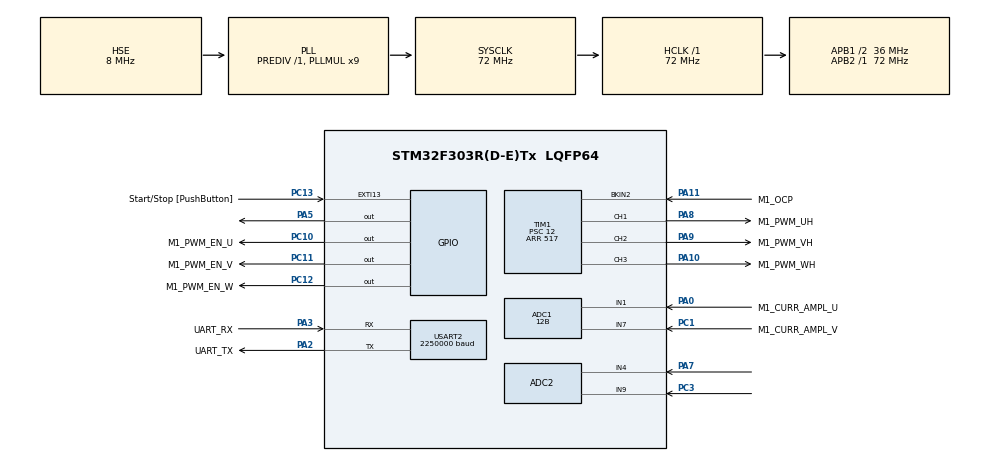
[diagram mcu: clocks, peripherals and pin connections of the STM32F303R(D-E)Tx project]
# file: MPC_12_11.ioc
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ADC1.Channel-1\#ChannelRegularConversion=ADC_CHANNEL_1
ADC1.Channel-2\#ChannelRegularConversion=ADC_CHANNEL_7
ADC1.ContinuousConvMode=ENABLE
ADC1.DMAContinuousRequests=DISABLE
ADC1.DataAlign=ADC_DATAALIGN_RIGHT
ADC1.DiscontinuousConvMode=DISABLE
ADC1.EOCSelection=ADC_EOC_SINGLE_CONV
ADC1.EnableAnalogWatchDog1=false
ADC1.EnableAnalogWatchDog2=false
ADC1.EnableAnalogWatchDog3=false
ADC1.EnableInjectedConversion=DISABLE
ADC1.EnableRegularConversion=ENABLE
ADC1.ExternalTrigConv=ADC_SOFTWARE_START
ADC1.ExternalTrigConvEdge=ADC_EXTERNALTRIGCONVEDGE_NONE
ADC1.LowPowerAutoWait=DISABLE
ADC1.NbrOfConversion=2
ADC1.NbrOfConversionFlag=1
ADC1.Offset-1\#ChannelRegularConversion=0
ADC1.Offset-2\#ChannelRegularConversion=0
ADC1.OffsetNumber-1\#ChannelRegularConversion=ADC_OFFSET_NONE
ADC1.OffsetNumber-2\#ChannelRegularConversion=ADC_OFFSET_NONE
ADC1.Overrun=ADC_OVR_DATA_OVERWRITTEN
ADC1.Rank-1\#ChannelRegularConversion=1
ADC1.Rank-2\#ChannelRegularConversion=2
ADC1.Resolution=ADC_RESOLUTION_12B
ADC1.SamplingTime-1\#ChannelRegularConversion=ADC_SAMPLETIME_1CYCLE_5
ADC1.SamplingTime-2\#ChannelRegularConversion=ADC_SAMPLETIME_1CYCLE_5
ADC1.ScanConvMode=ADC_SCAN_ENABLE
ADC1.master=1
ADC2.Channel-19\#ChannelRegularConversion=ADC_CHANNEL_4
ADC2.Channel-20\#ChannelRegularConversion=ADC_CHANNEL_9
ADC2.ContinuousConvMode=ENABLE
ADC2.NbrOfConversion=2
ADC2.NbrOfConversionFlag=1
ADC2.Offset-19\#ChannelRegularConversion=0
ADC2.Offset-20\#ChannelRegularConversion=0
ADC2.OffsetNumber-19\#ChannelRegularConversion=ADC_OFFSET_NONE
ADC2.OffsetNumber-20\#ChannelRegularConversion=ADC_OFFSET_NONE
ADC2.Rank-19\#ChannelRegularConversion=1
ADC2.Rank-20\#ChannelRegularConversion=2
ADC2.SamplingTime-19\#ChannelRegularConversion=ADC_SAMPLETIME_1CYCLE_5
ADC2.SamplingTime-20\#ChannelRegularConversion=ADC_SAMPLETIME_1CYCLE_5
Dma.ADC1.2.Direction=DMA_PERIPH_TO_MEMORY
Dma.ADC1.2.Instance=DMA1_Channel1
Dma.ADC1.2.MemDataAlignment=DMA_MDATAALIGN_WORD
Dma.ADC1.2.MemInc=DMA_MINC_ENABLE
Dma.ADC1.2.Mode=DMA_CIRCULAR
Dma.ADC1.2.PeriphDataAlignment=DMA_PDATAALIGN_WORD
Dma.ADC1.2.PeriphInc=DMA_PINC_DISABLE
Dma.ADC1.2.Priority=DMA_PRIORITY_LOW
Dma.ADC2.3.Direction=DMA_PERIPH_TO_MEMORY
Dma.ADC2.3.Instance=DMA2_Channel1
Dma.ADC2.3.MemDataAlignment=DMA_MDATAALIGN_WORD
Dma.ADC2.3.MemInc=DMA_MINC_ENABLE
Dma.ADC2.3.Mode=DMA_CIRCULAR
Dma.ADC2.3.PeriphDataAlignment=DMA_PDATAALIGN_WORD
Dma.ADC2.3.PeriphInc=DMA_PINC_DISABLE
Dma.ADC2.3.Priority=DMA_PRIORITY_LOW
Dma.Request0=USART2_RX
Dma.Request1=USART2_TX
Dma.Request2=ADC1
Dma.Request3=ADC2
Dma.USART2_RX.0.Direction=DMA_PERIPH_TO_MEMORY
Dma.USART2_RX.0.Instance=DMA1_Channel6
Dma.USART2_RX.0.MemDataAlignment=DMA_MDATAALIGN_BYTE
Dma.USART2_RX.0.MemInc=DMA_MINC_ENABLE
Dma.USART2_RX.0.Mode=DMA_CIRCULAR
Dma.USART2_RX.0.PeriphDataAlignment=DMA_PDATAALIGN_BYTE
Dma.USART2_RX.0.PeriphInc=DMA_PINC_DISABLE
Dma.USART2_RX.0.Priority=DMA_PRIORITY_LOW
Dma.USART2_TX.1.Direction=DMA_MEMORY_TO_PERIPH
Dma.USART2_TX.1.Instance=DMA1_Channel7
Dma.USART2_TX.1.MemDataAlignment=DMA_MDATAALIGN_BYTE
Dma.USART2_TX.1.MemInc=DMA_MINC_ENABLE
Dma.USART2_TX.1.Mode=DMA_NORMAL
Dma.USART2_TX.1.PeriphDataAlignment=DMA_PDATAALIGN_BYTE
Dma.USART2_TX.1.PeriphInc=DMA_PINC_DISABLE
Dma.USART2_TX.1.Priority=DMA_PRIORITY_LOW
Mcu.Family=STM32F3
Mcu.Name=STM32F303R(D-E)Tx
Mcu.Package=LQFP64
NVIC.EXTI15_10_IRQn=true\:3\:0\:false\:false\:true\:true\:true
NVIC.PriorityGroup=NVIC_PRIORITYGROUP_3
NVIC.TIM1_CC_IRQn=true\:0\:0\:false\:true\:true\:1\:true\:true
PA0.GPIO_Label=M1_CURR_AMPL_U
PA0.Mode=IN1-Single-Ended
PA0.Signal=ADC1_IN1
PA10.GPIO_Label=M1_PWM_WH
PA10.GPIO_PuPd=GPIO_PULLDOWN
PA10.GPIO_Speed=GPIO_SPEED_FREQ_HIGH
PA10.Signal=S_TIM1_CH3
PA11.GPIO_Label=M1_OCP
PA11.GPIO_PuPd=GPIO_PULLUP
PA11.Mode=Activate-Break-Input-2
PA11.Signal=TIM1_BKIN2
PA13.GPIO_Label=TMS
PA13.Mode=Serial_Wire
PA13.Signal=SYS_JTMS-SWDIO
PA14.GPIO_Label=TCK
PA14.Mode=Serial_Wire
PA14.Signal=SYS_JTCK-SWCLK
PA2.GPIO_Label=UART_TX
PA2.GPIO_Mode=GPIO_MODE_AF_PP
PA2.GPIO_PuPd=GPIO_NOPULL
PA2.GPIO_Speed=GPIO_SPEED_FREQ_LOW
PA2.Mode=Asynchronous
PA2.Signal=USART2_TX
PA3.GPIO_Label=UART_RX
PA3.GPIO_Mode=GPIO_MODE_AF_PP
PA3.GPIO_PuPd=GPIO_NOPULL
PA3.GPIO_Speed=GPIO_SPEED_FREQ_LOW
PA3.Mode=Asynchronous
PA3.Signal=USART2_RX
PA5.Signal=GPIO_Output
PA7.Mode=IN4-Single-Ended
PA7.Signal=ADC2_IN4
PA8.GPIO_Label=M1_PWM_UH
PA8.GPIO_PuPd=GPIO_PULLDOWN
PA8.GPIO_Speed=GPIO_SPEED_FREQ_HIGH
PA8.Signal=S_TIM1_CH1
PA9.GPIO_Label=M1_PWM_VH
PA9.GPIO_PuPd=GPIO_PULLDOWN
PA9.GPIO_Speed=GPIO_SPEED_FREQ_HIGH
PA9.Signal=S_TIM1_CH2
PC1.GPIO_Label=M1_CURR_AMPL_V
PC1.Signal=ADCx_IN7
PC10.GPIO_Label=M1_PWM_EN_U
PC10.GPIO_PuPd=GPIO_PULLDOWN
PC10.GPIO_Speed=GPIO_SPEED_FREQ_HIGH
PC10.Signal=GPIO_Output
PC11.GPIO_Label=M1_PWM_EN_V
PC11.GPIO_PuPd=GPIO_PULLDOWN
PC11.GPIO_Speed=GPIO_SPEED_FREQ_HIGH
PC11.Signal=GPIO_Output
PC12.GPIO_Label=M1_PWM_EN_W
PC12.GPIO_PuPd=GPIO_PULLDOWN
PC12.GPIO_Speed=GPIO_SPEED_FREQ_HIGH
PC12.Signal=GPIO_Output
PC13.GPIO_Label=Start/Stop [PushButton]
PC13.GPIO_ModeDefaultEXTI=GPIO_MODE_IT_FALLING
PC13.GPIO_PuPd=GPIO_NOPULL
PC13.Signal=GPXTI13
PC3.Signal=ADCx_IN9
PF0-OSC_IN.Mode=HSE-External-Oscillator
PF0-OSC_IN.Signal=RCC_OSC_IN
PF1-OSC_OUT.Mode=HSE-External-Oscillator
PF1-OSC_OUT.Signal=RCC_OSC_OUT
ProjectManager.HeapSize=0x200
ProjectManager.StackSize=0x400
ProjectManager.TargetToolchain=STM32CubeIDE
RCC.AHBFreq_Value=72000000
RCC.APB1CLKDivider=RCC_HCLK_DIV2
RCC.APB1Freq_Value=36000000
RCC.APB1TimFreq_Value=72000000
RCC.APB2Freq_Value=72000000
RCC.APB2TimFreq_Value=72000000
RCC.CortexFreq_Value=72000000
RCC.HCLKFreq_Value=72000000
RCC.HSE_VALUE=8000000
RCC.HSI_VALUE=8000000
RCC.LSE_VALUE=32768
RCC.PLLMUL=RCC_PLL_MUL9
RCC.PLLSourceVirtual=RCC_PLLSOURCE_HSE
RCC.SYSCLKFreq_VALUE=72000000
RCC.SYSCLKSourceVirtual=RCC_SYSCLKSOURCE_PLLCLK
RCC.TIM1Selection=RCC_TIM1CLK_PLLCLK
RCC.TIM34Selection=RCC_TIM34CLK_PLLCLK
RCC.TIM8Selection=RCC_TIM8CLK_PLLCLK
RCC.USBFreq_Value=72000000
RCC.Usart2ClockSelection=RCC_USART2CLKSOURCE_SYSCLK
SH.ADCx_IN7.0=ADC1_IN7,IN7-Single-Ended
SH.ADCx_IN9.0=ADC2_IN9,IN9-Single-Ended
SH.S_TIM1_CH1.0=TIM1_CH1,PWM Generation1 CH1
SH.S_TIM1_CH2.0=TIM1_CH2,PWM Generation2 CH2
SH.S_TIM1_CH3.0=TIM1_CH3,PWM Generation3 CH3
TIM1.AutoReloadPreload=TIM_AUTORELOAD_PRELOAD_ENABLE
TIM1.AutomaticOutput=TIM_AUTOMATICOUTPUT_DISABLE
TIM1.Break2Filter=3
TIM1.Break2Polarity=TIM_BREAK2POLARITY_LOW
TIM1.Break2State=TIM_BREAK2_ENABLE
TIM1.BreakFilter=0
TIM1.BreakPolarity=TIM_BREAKPOLARITY_HIGH
TIM1.BreakState=TIM_BREAK_DISABLE
TIM1.Channel-PWM\ Generation1\ CH1=TIM_CHANNEL_1
TIM1.Channel-PWM\ Generation2\ CH2=TIM_CHANNEL_2
TIM1.Channel-PWM\ Generation3\ CH3=TIM_CHANNEL_3
TIM1.Channel-PWM\ Generation4\ No\ Output=TIM_CHANNEL_4
TIM1.ClearInputSource=TIM_CLEARINPUTSOURCE_NONE
TIM1.ClockDivision=TIM_CLOCKDIVISION_DIV1
TIM1.CounterMode=TIM_COUNTERMODE_CENTERALIGNED1
TIM1.LockLevel=TIM_LOCKLEVEL_1
TIM1.OCIdleState_1=TIM_OCIDLESTATE_RESET
TIM1.OCIdleState_2=TIM_OCIDLESTATE_RESET
TIM1.OCIdleState_3=TIM_OCIDLESTATE_RESET
TIM1.OCIdleState_4=TIM_OCIDLESTATE_RESET
TIM1.OCMode_PWM-PWM\ Generation1\ CH1=TIM_OCMODE_PWM1
TIM1.OCMode_PWM-PWM\ Generation2\ CH2=TIM_OCMODE_PWM1
TIM1.OCMode_PWM-PWM\ Generation3\ CH3=TIM_OCMODE_PWM1
TIM1.OCMode_PWM-PWM\ Generation4\ No\ Output=TIM_OCMODE_PWM2
TIM1.OCPolarity_1=TIM_OCPOLARITY_HIGH
TIM1.OCPolarity_2=TIM_OCPOLARITY_HIGH
TIM1.OCPolarity_3=TIM_OCPOLARITY_HIGH
TIM1.OCPolarity_4=TIM_OCPOLARITY_HIGH
TIM1.OffStateIDLEMode=TIM_OSSI_ENABLE
TIM1.OffStateRunMode=TIM_OSSR_ENABLE
TIM1.Period=517
TIM1.Prescaler=12
TIM1.Pulse-PWM\ Generation1\ CH1=0
TIM1.Pulse-PWM\ Generation2\ CH2=0
TIM1.Pulse-PWM\ Generation3\ CH3=0
TIM1.Pulse-PWM\ Generation4\ No\ Output=512
TIM1.RepetitionCounter=0
TIM1.TIM_MasterOutputTrigger=TIM_TRGO_OC4REF
TIM1.TIM_MasterOutputTrigger2=TIM_TRGO2_UPDATE
TIM1.TIM_MasterSlaveMode=TIM_MASTERSLAVEMODE_DISABLE
USART2.BaudRate=2250000
USART2.DMADisableonRxErrorParam=ADVFEATURE_DMA_DISABLEONRXERROR
USART2.OneBitSampling=UART_ONE_BIT_SAMPLE_ENABLE
USART2.OverSampling=UART_OVERSAMPLING_8
USART2.VirtualMode-Asynchronous=VM_ASYNC
USART2.WordLength=WORDLENGTH_8B
VP_TIM1_VS_ClockSourceINT.Mode=Internal
VP_TIM1_VS_no_output4.Mode=PWM Generation4 No Output
board=custom

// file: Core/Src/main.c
/* USER CODE BEGIN Header */
/**
  ******************************************************************************
  * @file           : main.c
  * @brief          : Main program body
  ******************************************************************************
  * @attention
  *
  * <h2><center>&copy; Copyright (c) 2021 STMicroelectronics.
  * All rights reserved.</center></h2>
  *
  * This software component is licensed by ST under Ultimate Liberty license
  * SLA0044, the "License"; You may not use this file except in compliance with
  * the License. You may obtain a copy of the License at:
  *                             www.st.com/SLA0044
  *
  ******************************************************************************
  */
/* USER CODE END Header */
#include "main.h"

/* USER CODE BEGIN Includes */
//
//#include <string.h>
//#include <stdio.h>
/* USER CODE END Includes */

ADC_HandleTypeDef hadc1;
ADC_HandleTypeDef hadc2;
DMA_HandleTypeDef hdma_adc1;
DMA_HandleTypeDef hdma_adc2;

TIM_HandleTypeDef htim1;

UART_HandleTypeDef huart2;
DMA_HandleTypeDef hdma_usart2_rx;
DMA_HandleTypeDef hdma_usart2_tx;

void SystemClock_Config(void);
static void MX_GPIO_Init(void);
static void MX_DMA_Init(void);
static void MX_ADC1_Init(void);
static void MX_TIM1_Init(void);
static void MX_USART2_UART_Init(void);
static void MX_ADC2_Init(void);
static void MX_NVIC_Init(void);

int main(void)
{

  /* MCU Configuration--------------------------------------------------------*/

  /* Reset of all peripherals, Initializes the Flash interface and the Systick. */
  HAL_Init();

  /* Configure the system clock */
  SystemClock_Config();

  /* Initialize all configured peripherals */
  MX_GPIO_Init();
  MX_DMA_Init();
  MX_ADC1_Init();
  MX_TIM1_Init();
  MX_USART2_UART_Init();
  MX_ADC2_Init();

  /* Initialize interrupts */
  MX_NVIC_Init();
  /* USER CODE BEGIN 2 */

  	// Calibrate ADCs
	HAL_ADCEx_Calibration_Start(&hadc1, ADC_SINGLE_ENDED);
	HAL_ADCEx_Calibration_Start(&hadc2, ADC_SINGLE_ENDED);

	// Enable MOSFET drivers
	HAL_GPIO_WritePin(GPIOC, GPIO_PIN_10, 1);
	HAL_GPIO_WritePin(GPIOC, GPIO_PIN_11, 1);
	HAL_GPIO_WritePin(GPIOC, GPIO_PIN_12, 1);

	// Start timers
	HAL_TIM_PWM_Start_IT(&htim1, TIM_CHANNEL_4);
	HAL_TIM_PWM_Start(&htim1, TIM_CHANNEL_1);
	HAL_TIM_PWM_Start(&htim1, TIM_CHANNEL_2);
	HAL_TIM_PWM_Start(&htim1, TIM_CHANNEL_3);

  /* USER CODE END 2 */

  /* Infinite loop */
  while (1)
  {

  }
}

void SystemClock_Config(void)
{
  RCC_OscInitTypeDef RCC_OscInitStruct = {0};
  RCC_ClkInitTypeDef RCC_ClkInitStruct = {0};
  RCC_PeriphCLKInitTypeDef PeriphClkInit = {0};

  /** Initializes the RCC Oscillators according to the specified parameters
  * in the RCC_OscInitTypeDef structure.
  */
  RCC_OscInitStruct.OscillatorType = RCC_OSCILLATORTYPE_HSE;
  RCC_OscInitStruct.HSEState = RCC_HSE_ON;
  RCC_OscInitStruct.HSIState = RCC_HSI_ON;
  RCC_OscInitStruct.PLL.PLLState = RCC_PLL_ON;
  RCC_OscInitStruct.PLL.PLLSource = RCC_PLLSOURCE_HSE;
  RCC_OscInitStruct.PLL.PLLMUL = RCC_PLL_MUL9;
  RCC_OscInitStruct.PLL.PREDIV = RCC_PREDIV_DIV1;
  if (HAL_RCC_OscConfig(&RCC_OscInitStruct) != HAL_OK)
  {
    Error_Handler();
  }
  /** Initializes the CPU, AHB and APB buses clocks
  */
  RCC_ClkInitStruct.ClockType = RCC_CLOCKTYPE_HCLK|RCC_CLOCKTYPE_SYSCLK
                              |RCC_CLOCKTYPE_PCLK1|RCC_CLOCKTYPE_PCLK2;
  RCC_ClkInitStruct.SYSCLKSource = RCC_SYSCLKSOURCE_PLLCLK;
  RCC_ClkInitStruct.AHBCLKDivider = RCC_SYSCLK_DIV1;
  RCC_ClkInitStruct.APB1CLKDivider = RCC_HCLK_DIV2;
  RCC_ClkInitStruct.APB2CLKDivider = RCC_HCLK_DIV1;

  if (HAL_RCC_ClockConfig(&RCC_ClkInitStruct, FLASH_LATENCY_2) != HAL_OK)
  {
    Error_Handler();
  }
  PeriphClkInit.PeriphClockSelection = RCC_PERIPHCLK_USART2|RCC_PERIPHCLK_TIM1
                              |RCC_PERIPHCLK_ADC12;
  PeriphClkInit.Usart2ClockSelection = RCC_USART2CLKSOURCE_SYSCLK;
  PeriphClkInit.Adc12ClockSelection = RCC_ADC12PLLCLK_DIV1;
  PeriphClkInit.Tim1ClockSelection = RCC_TIM1CLK_PLLCLK;
  if (HAL_RCCEx_PeriphCLKConfig(&PeriphClkInit) != HAL_OK)
  {
    Error_Handler();
  }
}

/**
  * @brief NVIC Configuration.
  * @retval None
  */
static void MX_NVIC_Init(void)
{
  /* TIM1_CC_IRQn interrupt configuration */
  HAL_NVIC_SetPriority(TIM1_CC_IRQn, 0, 0);
  HAL_NVIC_EnableIRQ(TIM1_CC_IRQn);
}

static void MX_ADC1_Init(void)
{

  ADC_MultiModeTypeDef multimode = {0};
  ADC_ChannelConfTypeDef sConfig = {0};

  /** Common config
  */
  hadc1.Instance = ADC1;
  hadc1.Init.ClockPrescaler = ADC_CLOCK_ASYNC_DIV1;
  hadc1.Init.Resolution = ADC_RESOLUTION_12B;
  hadc1.Init.ScanConvMode = ADC_SCAN_ENABLE;
  hadc1.Init.ContinuousConvMode = ENABLE;
  hadc1.Init.DiscontinuousConvMode = DISABLE;
  hadc1.Init.ExternalTrigConvEdge = ADC_EXTERNALTRIGCONVEDGE_NONE;
  hadc1.Init.ExternalTrigConv = ADC_SOFTWARE_START;
  hadc1.Init.DataAlign = ADC_DATAALIGN_RIGHT;
  hadc1.Init.NbrOfConversion = 2;
  hadc1.Init.DMAContinuousRequests = DISABLE;
  hadc1.Init.EOCSelection = ADC_EOC_SINGLE_CONV;
  hadc1.Init.LowPowerAutoWait = DISABLE;
  hadc1.Init.Overrun = ADC_OVR_DATA_OVERWRITTEN;
  if (HAL_ADC_Init(&hadc1) != HAL_OK)
  {
    Error_Handler();
  }
  /** Configure the ADC multi-mode
  */
  multimode.Mode = ADC_MODE_INDEPENDENT;
  if (HAL_ADCEx_MultiModeConfigChannel(&hadc1, &multimode) != HAL_OK)
  {
    Error_Handler();
  }
  /** Configure Regular Channel
  */
  sConfig.Channel = ADC_CHANNEL_1;
  sConfig.Rank = ADC_REGULAR_RANK_1;
  sConfig.SingleDiff = ADC_SINGLE_ENDED;
  sConfig.SamplingTime = ADC_SAMPLETIME_1CYCLE_5;
  sConfig.OffsetNumber = ADC_OFFSET_NONE;
  sConfig.Offset = 0;
  if (HAL_ADC_ConfigChannel(&hadc1, &sConfig) != HAL_OK)
  {
    Error_Handler();
  }
  /** Configure Regular Channel
  */
  sConfig.Channel = ADC_CHANNEL_7;
  sConfig.Rank = ADC_REGULAR_RANK_2;
  if (HAL_ADC_ConfigChannel(&hadc1, &sConfig) != HAL_OK)
  {
    Error_Handler();
  }

}

static void MX_ADC2_Init(void)
{

  ADC_ChannelConfTypeDef sConfig = {0};

  /** Common config
  */
  hadc2.Instance = ADC2;
  hadc2.Init.ClockPrescaler = ADC_CLOCK_ASYNC_DIV1;
  hadc2.Init.Resolution = ADC_RESOLUTION_12B;
  hadc2.Init.ScanConvMode = ADC_SCAN_ENABLE;
  hadc2.Init.ContinuousConvMode = ENABLE;
  hadc2.Init.DiscontinuousConvMode = DISABLE;
  hadc2.Init.ExternalTrigConvEdge = ADC_EXTERNALTRIGCONVEDGE_NONE;
  hadc2.Init.ExternalTrigConv = ADC_SOFTWARE_START;
  hadc2.Init.DataAlign = ADC_DATAALIGN_RIGHT;
  hadc2.Init.NbrOfConversion = 2;
  hadc2.Init.DMAContinuousRequests = DISABLE;
  hadc2.Init.EOCSelection = ADC_EOC_SINGLE_CONV;
  hadc2.Init.LowPowerAutoWait = DISABLE;
  hadc2.Init.Overrun = ADC_OVR_DATA_OVERWRITTEN;
  if (HAL_ADC_Init(&hadc2) != HAL_OK)
  {
    Error_Handler();
  }
  /** Configure Regular Channel
  */
  sConfig.Channel = ADC_CHANNEL_4;
  sConfig.Rank = ADC_REGULAR_RANK_1;
  sConfig.SingleDiff = ADC_SINGLE_ENDED;
  sConfig.SamplingTime = ADC_SAMPLETIME_1CYCLE_5;
  sConfig.OffsetNumber = ADC_OFFSET_NONE;
  sConfig.Offset = 0;
  if (HAL_ADC_ConfigChannel(&hadc2, &sConfig) != HAL_OK)
  {
    Error_Handler();
  }
  /** Configure Regular Channel
  */
  sConfig.Channel = ADC_CHANNEL_9;
  sConfig.Rank = ADC_REGULAR_RANK_2;
  if (HAL_ADC_ConfigChannel(&hadc2, &sConfig) != HAL_OK)
  {
    Error_Handler();
  }

}

static void MX_TIM1_Init(void)
{

  TIM_ClockConfigTypeDef sClockSourceConfig = {0};
  TIM_MasterConfigTypeDef sMasterConfig = {0};
  TIM_OC_InitTypeDef sConfigOC = {0};
  TIM_BreakDeadTimeConfigTypeDef sBreakDeadTimeConfig = {0};

  htim1.Instance = TIM1;
  htim1.Init.Prescaler = 12;
  htim1.Init.CounterMode = TIM_COUNTERMODE_CENTERALIGNED1;
  htim1.Init.Period = 517;
  htim1.Init.ClockDivision = TIM_CLOCKDIVISION_DIV1;
  htim1.Init.RepetitionCounter = 0;
  htim1.Init.AutoReloadPreload = TIM_AUTORELOAD_PRELOAD_ENABLE;
  if (HAL_TIM_Base_Init(&htim1) != HAL_OK)
  {
    Error_Handler();
  }
  sClockSourceConfig.ClockSource = TIM_CLOCKSOURCE_INTERNAL;
  if (HAL_TIM_ConfigClockSource(&htim1, &sClockSourceConfig) != HAL_OK)
  {
    Error_Handler();
  }
  if (HAL_TIM_PWM_Init(&htim1) != HAL_OK)
  {
    Error_Handler();
  }
  sMasterConfig.MasterOutputTrigger = TIM_TRGO_OC4REF;
  sMasterConfig.MasterOutputTrigger2 = TIM_TRGO2_UPDATE;
  sMasterConfig.MasterSlaveMode = TIM_MASTERSLAVEMODE_DISABLE;
  if (HAL_TIMEx_MasterConfigSynchronization(&htim1, &sMasterConfig) != HAL_OK)
  {
    Error_Handler();
  }
  sConfigOC.OCMode = TIM_OCMODE_PWM1;
  sConfigOC.Pulse = 0;
  sConfigOC.OCPolarity = TIM_OCPOLARITY_HIGH;
  sConfigOC.OCNPolarity = TIM_OCNPOLARITY_HIGH;
  sConfigOC.OCFastMode = TIM_OCFAST_DISABLE;
  sConfigOC.OCIdleState = TIM_OCIDLESTATE_RESET;
  sConfigOC.OCNIdleState = TIM_OCNIDLESTATE_RESET;
  if (HAL_TIM_PWM_ConfigChannel(&htim1, &sConfigOC, TIM_CHANNEL_1) != HAL_OK)
  {
    Error_Handler();
  }
  if (HAL_TIM_PWM_ConfigChannel(&htim1, &sConfigOC, TIM_CHANNEL_2) != HAL_OK)
  {
    Error_Handler();
  }
  if (HAL_TIM_PWM_ConfigChannel(&htim1, &sConfigOC, TIM_CHANNEL_3) != HAL_OK)
  {
    Error_Handler();
  }
  sConfigOC.OCMode = TIM_OCMODE_PWM2;
  sConfigOC.Pulse = 512;
  if (HAL_TIM_PWM_ConfigChannel(&htim1, &sConfigOC, TIM_CHANNEL_4) != HAL_OK)
  {
    Error_Handler();
  }
  sBreakDeadTimeConfig.OffStateRunMode = TIM_OSSR_ENABLE;
  sBreakDeadTimeConfig.OffStateIDLEMode = TIM_OSSI_ENABLE;
  sBreakDeadTimeConfig.LockLevel = TIM_LOCKLEVEL_1;
  sBreakDeadTimeConfig.DeadTime = 0;
  sBreakDeadTimeConfig.BreakState = TIM_BREAK_DISABLE;
  sBreakDeadTimeConfig.BreakPolarity = TIM_BREAKPOLARITY_HIGH;
  sBreakDeadTimeConfig.BreakFilter = 0;
  sBreakDeadTimeConfig.Break2State = TIM_BREAK2_ENABLE;
  sBreakDeadTimeConfig.Break2Polarity = TIM_BREAK2POLARITY_LOW;
  sBreakDeadTimeConfig.Break2Filter = 3;
  sBreakDeadTimeConfig.AutomaticOutput = TIM_AUTOMATICOUTPUT_DISABLE;
  if (HAL_TIMEx_ConfigBreakDeadTime(&htim1, &sBreakDeadTimeConfig) != HAL_OK)
  {
    Error_Handler();
  }
  HAL_TIM_MspPostInit(&htim1);

}

static void MX_USART2_UART_Init(void)
{

  huart2.Instance = USART2;
  huart2.Init.BaudRate = 2250000;
  huart2.Init.WordLength = UART_WORDLENGTH_8B;
  huart2.Init.StopBits = UART_STOPBITS_1;
  huart2.Init.Parity = UART_PARITY_NONE;
  huart2.Init.Mode = UART_MODE_TX_RX;
  huart2.Init.HwFlowCtl = UART_HWCONTROL_NONE;
  huart2.Init.OverSampling = UART_OVERSAMPLING_8;
  huart2.Init.OneBitSampling = UART_ONE_BIT_SAMPLE_ENABLE;
  huart2.AdvancedInit.AdvFeatureInit = UART_ADVFEATURE_DMADISABLEONERROR_INIT;
  huart2.AdvancedInit.DMADisableonRxError = UART_ADVFEATURE_DMA_DISABLEONRXERROR;
  if (HAL_UART_Init(&huart2) != HAL_OK)
  {
    Error_Handler();
  }

}

static void MX_DMA_Init(void)
{

  /* DMA controller clock enable */
  __HAL_RCC_DMA1_CLK_ENABLE();
  __HAL_RCC_DMA2_CLK_ENABLE();

}

static void MX_GPIO_Init(void)
{
  GPIO_InitTypeDef GPIO_InitStruct = {0};

  /* GPIO Ports Clock Enable */
  __HAL_RCC_GPIOC_CLK_ENABLE();
  __HAL_RCC_GPIOF_CLK_ENABLE();
  __HAL_RCC_GPIOA_CLK_ENABLE();

  /*Configure GPIO pin Output Level */
  HAL_GPIO_WritePin(GPIOA, GPIO_PIN_5, GPIO_PIN_RESET);

  /*Configure GPIO pin Output Level */
  HAL_GPIO_WritePin(GPIOC, M1_PWM_EN_U_Pin|M1_PWM_EN_V_Pin|M1_PWM_EN_W_Pin, GPIO_PIN_RESET);

  /*Configure GPIO pin : Start_Stop_Pin */
  GPIO_InitStruct.Pin = Start_Stop_Pin;
  GPIO_InitStruct.Mode = GPIO_MODE_IT_FALLING;
  GPIO_InitStruct.Pull = GPIO_NOPULL;
  HAL_GPIO_Init(Start_Stop_GPIO_Port, &GPIO_InitStruct);

  /*Configure GPIO pin : PA5 */
  GPIO_InitStruct.Pin = GPIO_PIN_5;
  GPIO_InitStruct.Mode = GPIO_MODE_OUTPUT_PP;
  GPIO_InitStruct.Pull = GPIO_NOPULL;
  GPIO_InitStruct.Speed = GPIO_SPEED_FREQ_LOW;
  HAL_GPIO_Init(GPIOA, &GPIO_InitStruct);

  /*Configure GPIO pins : M1_PWM_EN_U_Pin M1_PWM_EN_V_Pin M1_PWM_EN_W_Pin */
  GPIO_InitStruct.Pin = M1_PWM_EN_U_Pin|M1_PWM_EN_V_Pin|M1_PWM_EN_W_Pin;
  GPIO_InitStruct.Mode = GPIO_MODE_OUTPUT_PP;
  GPIO_InitStruct.Pull = GPIO_PULLDOWN;
  GPIO_InitStruct.Speed = GPIO_SPEED_FREQ_HIGH;
  HAL_GPIO_Init(GPIOC, &GPIO_InitStruct);

  /* EXTI interrupt init*/
  HAL_NVIC_SetPriority(EXTI15_10_IRQn, 3, 0);
  HAL_NVIC_EnableIRQ(EXTI15_10_IRQn);

}

void Error_Handler(void)
{
  __disable_irq();
  while (1)
  {
  }
}

/************************ (C) COPYRIGHT STMicroelectronics *****END OF FILE****/
